# CCG2 register map
File version: 1.0
CCG2 family is the 2nd generation, USB Type-C controller targeted for Electronically Marked Cable Assembly.
CPU: CM0 r1p0, little endian, no MPU, no FPU, 2 interrupt priority bits
Registers are 32-bit, read-write, reset 0x0 unless marked. A register's access mark holds for its fields unless they carry their own. Offsets are from the block's base; lines under a group give offsets from that group; [hi:lo] are bit positions; {n}, {i} and the like mark numbered series; 'fields as' and 'values as' point back to an identical list; <NAME> marks a mode.

## Memory map
0x40010000 PERI size 0x10000
0x40020000 HSIOM size 0x4000
0x40030000 SRSSLT size 0x10000
0x40040000 GPIO size 0x4000
0x40050000 SCB0 size 0x10000
0x40060000 SCB1 size 0x10000
0x40070000 TCPWM size 0x10000
0x40080000 USBPD size 0x10000
0x40100000 CPUSS size 0x1000

## Interrupts
0 PICU0 (GPIO)
1 PICU1 (GPIO)
2 PICU2 (GPIO)
3 GANGEDPICU (GPIO)
4 USBPD0 (USBPD)
5 WDT (SRSSLT)
6 SCB0
7 SCB1
8 SPCIF (SRSSLT)
9 USBPD1 (USBPD)
10 TCPWM0 (TCPWM)
11 TCPWM1 (TCPWM)
12 TCPWM2 (TCPWM)
13 TCPWM3 (TCPWM)
14 TCPWM4 (TCPWM)
15 TCPWM5 (TCPWM)

## HSIOM
Base 0x40020000
0x00 HSIOM_PRT0 group
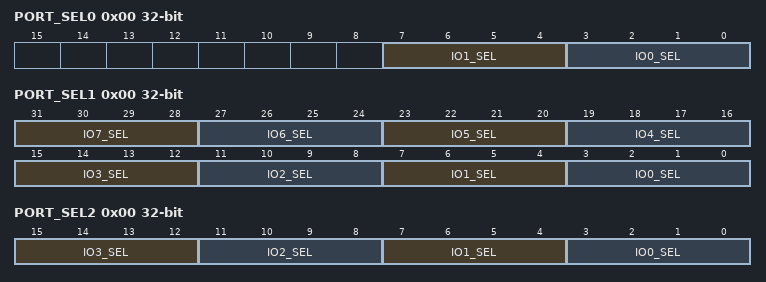
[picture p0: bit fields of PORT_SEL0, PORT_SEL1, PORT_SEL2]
  0x00 PORT_SEL0
    [7:4] IO1_SEL
      10=SCB0_uart_rts; 12=CPUSS0_swd_clk; 13=SCB0_spi_miso; 15=SCB0_i2c_scl; 0=GPIO
    [3:0] IO0_SEL
      8=SRSS0_ext_clk; 10=SCB0_uart_cts; 12=CPUSS0_swd_data; 13=SCB0_spi_select0; 15=SCB0_i2c_sda; 0=GPIO
0x100 HSIOM_PRT1 group
  0x00 PORT_SEL1
    [31:28] IO7_SEL
      8=TCPWM4_line; 9=TCPWM4_tr_compare_match; 10=SCB0_uart_tx; 11=TCPWM4_tr_overflow; 12=USBPD0_tx_data; 13=SCB0_spi_mosi; 15=SCB0_i2c_sda; 0=GPIO
    [27:24] IO6_SEL
      0=GPIO
    [23:20] IO5_SEL
      8=TCPWM3_line; 9=TCPWM3_tr_compare_match; 10=SCB1_uart_rts; 11=TCPWM3_tr_overflow; 12=USBPD0_cmp_out; 13=SCB0_spi_miso; 14=SCB1_spi_select0; 0=GPIO
    [19:16] IO4_SEL
      0=GPIO
    [15:12] IO3_SEL
      8=SRSS0_ext_clk; 10=SCB1_uart_rx; 13=SCB0_spi_select0; 14=SCB1_spi_miso; 15=SCB1_i2c_sda; 0=GPIO
    [11:8] IO2_SEL
      8=TCPWM2_line; 9=TCPWM2_tr_compare_match; 11=TCPWM2_tr_overflow; 12=CPUSS0_swd_clk; 0=GPIO
    [7:4] IO1_SEL
      8=TCPWM1_line; 9=TCPWM1_tr_compare_match; 10=SCB1_uart_cts; 11=TCPWM1_tr_overflow; 12=CPUSS0_swd_data; 14=SCB1_spi_mosi; 0=GPIO
    [3:0] IO0_SEL
      8=TCPWM0_line; 9=TCPWM0_tr_compare_match; 10=SCB1_uart_tx; 11=TCPWM0_tr_overflow; 12=USBPD0_tx_data_en; 14=SCB1_spi_clk; 15=SCB1_i2c_scl; 0=GPIO
0x200 HSIOM_PRT2 group
  0x00 PORT_SEL2
    [15:12] IO3_SEL
      0=GPIO
    [11:8] IO2_SEL
      0=GPIO
    [7:4] IO1_SEL
      8=TCPWM5_line; 9=TCPWM5_tr_compare_match; 10=SCB0_uart_rx; 11=TCPWM5_tr_overflow; 12=USBPD0_cmp_out; 13=SCB0_spi_clk; 15=SCB0_i2c_scl; 0=GPIO
    [3:0] IO0_SEL
      0=GPIO
